VERSION ""

NS_ :

BS_:

BU_: DASH VectorDatalogger MotecDatalogger KvaserDatalogger PDM SENSOR_BOARD CAN_NODE_3 CAN_NODE_2 CAN_NODE_1 CAN_NODE_0 VCU BMS INV U2C

BO_ 3221225472 VECTOR__INDEPENDENT_SIG_MSG: 0 Vector__XXX
 SG_ OCT_GPS_TimeUCT : 0|25@1+ (0.01,0) [0|24000000] "" Vector__XXX
 SG_ OCT_GPS_NumSats : 0|7@1+ (1,0) [0|99] "" Vector__XXX
 SG_ OCT_GPS_HDOP : 0|8@1+ (1,0) [0|256] "" Vector__XXX
 SG_ OCT_GPS_Longitude : 0|32@1- (0.0001,0) [0|1809999999] "" Vector__XXX
 SG_ OCT_GPS_Latitude : 0|31@1- (0.0001,0) [0|909999999] "" Vector__XXX

BO_ 2033 VCU_Config_Torque_Map: 8 Vector__XXX
 SG_ MAX_Torque : 0|16@1+ (1,0) [0|0] "" Vector__XXX
 SG_ Torque_Map_Deadzone : 16|32@1- (1,0) [0|0] "" Vector__XXX

BO_ 2032 VCU_Config: 8 Vector__XXX
 SG_ VCU_CONFIG_Multiplexor M : 7|8@0- (1,0) [0|0] "" Vector__XXX
 SG_ BPS_MIN_Mapped m7 : 40|16@1+ (1,0) [0|0] "" Vector__XXX
 SG_ BPS_MIN_ADC m7 : 24|16@1+ (1,0) [0|0] "" Vector__XXX
 SG_ BPS_MAX_Mapped m7 : 8|16@1+ (1,0) [0|0] "" Vector__XXX
 SG_ BPS_MAX_ADC m6 : 40|16@1+ (1,0) [0|0] "" Vector__XXX
 SG_ BPS_Full_Press_FRACT m6 : 8|32@1- (1,0) [0|0] "" Vector__XXX
 SG_ APPS_MAX_Discrepancy m5 : 8|32@1+ (1,0) [0|0] "" Vector__XXX
 SG_ APPS2_OOB_FRACT m4 : 24|32@1- (1,0) [0|0] "" Vector__XXX
 SG_ APPS2_MIN_Mapped m4 : 8|16@1+ (1,0) [0|0] "" Vector__XXX
 SG_ APPS2_MIN_ADC m3 : 40|16@1+ (1,0) [0|0] "" Vector__XXX
 SG_ APPS2_MAX_Mapped m3 : 24|16@1+ (1,0) [0|0] "" Vector__XXX
 SG_ APPS2_MAX_ADC m3 : 8|16@1+ (1,0) [0|0] "" Vector__XXX
 SG_ APPS1_OOB_FRACT m2 : 24|32@1- (1,0) [0|0] "" Vector__XXX
 SG_ APPS1_MIN_Mapped m2 : 8|16@1+ (1,0) [0|0] "" Vector__XXX
 SG_ APPS1_MAX_Mapped m1 : 40|16@1+ (1,0) [0|0] "" Vector__XXX
 SG_ APPS1_MAX_ADC m1 : 24|16@1+ (1,0) [0|0] "" Vector__XXX
 SG_ APPS1_MIN_ADC m1 : 8|16@1+ (1,0) [0|0] "" Vector__XXX

BO_ 1664 SB_Strain: 3 SENSOR_BOARD
 SG_ SB_Strain_9 m9 : 8|16@1+ (1.953125E-06,-0.004) [-0.004|0.123998046875] "m/m" Vector__XXX
 SG_ SB_Strain_8 m8 : 8|16@1+ (1.953125E-06,-0.004) [-0.004|0.123998046875] "m/m" Vector__XXX
 SG_ SB_Strain_7 m7 : 8|16@1+ (1.953125E-06,-0.004) [-0.004|0.123998046875] "m/m" Vector__XXX
 SG_ SB_Strain_6 m6 : 8|16@1+ (1.953125E-06,-0.004) [-0.004|0.123998046875] "m/m" Vector__XXX
 SG_ SB_Strain_5 m5 : 8|16@1+ (1.953125E-06,-0.004) [-0.004|0.123998046875] "m/m" Vector__XXX
 SG_ SB_Strain_4 m4 : 8|16@1+ (1.953125E-06,-0.004) [-0.004|0.123998046875] "m/m" Vector__XXX
 SG_ SB_Strain_3 m3 : 8|16@1+ (1.953125E-06,-0.004) [-0.004|0.123998046875] "m/m" Vector__XXX
 SG_ SB_Strain_2 m2 : 8|16@1+ (1.953125E-06,-0.004) [-0.004|0.123998046875] "m/m" Vector__XXX
 SG_ SB_Strain_12 m12 : 8|16@1+ (1.953125E-06,-0.004) [-0.004|0.123998046875] "m/m" Vector__XXX
 SG_ SB_Strain_11 m11 : 8|16@1+ (1.953125E-06,-0.004) [-0.004|0.123998046875] "m/m" Vector__XXX
 SG_ SB_Strain_10 m10 : 8|16@1+ (1.953125E-06,-0.004) [-0.004|0.123998046875] "m/m" Vector__XXX
 SG_ SB_Strain_1 m1 : 8|16@1+ (1.953125E-06,-0.004) [-0.004|0.123998046875] "m/m" Vector__XXX
 SG_ SB_Strain_multiplexor M : 0|4@1- (1,0) [0|12] "Num" Vector__XXX

BO_ 1648 CAN_NODE_0: 8 CAN_NODE_0
 SG_ CAN_NODE_THERM_2 m2 : 16|8@1- (1,0) [-128|127] "�C"  DASH,KvaserDatalogger,MotecDatalogger,VectorDatalogger
 SG_ CAN_NODE_THERM_1 m2 : 8|8@1- (1,0) [-128|127] "�C"  DASH,KvaserDatalogger,MotecDatalogger,VectorDatalogger
 SG_ CAN_NODE_PD_9 m1 : 40|12@1+ (0.00402832,0) [0|16.4959704] "V"  DASH,KvaserDatalogger,MotecDatalogger,VectorDatalogger
 SG_ CAN_NODE_PD_8 m1 : 28|12@1+ (0.00402832,0) [0|16.4959704] "V"  DASH,KvaserDatalogger,MotecDatalogger,VectorDatalogger
 SG_ CAN_NODE_PD_7 m1 : 16|12@1+ (0.00402832,0) [0|16.4959704] "V"  DASH,KvaserDatalogger,MotecDatalogger,VectorDatalogger
 SG_ CAN_NODE_PD_6 m1 : 4|12@1+ (0.00402832,0) [0|16.4959704] "V"  DASH,KvaserDatalogger,MotecDatalogger,VectorDatalogger
 SG_ CAN_NODE_PD_5 m0 : 52|12@1+ (0.00402832,0) [0|16.4959704] "V"  DASH,KvaserDatalogger,MotecDatalogger,VectorDatalogger
 SG_ CAN_NODE_PD_4 m0 : 40|12@1+ (0.00402832,0) [0|16.4959704] "V"  DASH,KvaserDatalogger,MotecDatalogger,VectorDatalogger
 SG_ CAN_NODE_PD_3 m0 : 28|12@1+ (0.00402832,0) [0|16.4959704] "V"  DASH,KvaserDatalogger,MotecDatalogger,VectorDatalogger
 SG_ CAN_NODE_PD_2 m0 : 16|12@1+ (0.00402832,0) [0|16.4959704] "V"  DASH,KvaserDatalogger,MotecDatalogger,VectorDatalogger
 SG_ CAN_NODE_PD_10 m1 : 52|12@1+ (0.00402832,0) [0|16.4959704] "V"  DASH,KvaserDatalogger,MotecDatalogger,VectorDatalogger
 SG_ CAN_NODE_PD_1 m0 : 4|12@1+ (0.00402832,0) [0|16.4959704] "V"  DASH,KvaserDatalogger,MotecDatalogger,VectorDatalogger
 SG_ CAN_NODE_multiplexor M : 0|4@1+ (1,0) [0|15] ""  DASH,KvaserDatalogger,MotecDatalogger,VectorDatalogger

BO_ 1649 CAN_NODE_1: 8 CAN_NODE_1
 SG_ CAN_NODE_THERM_2 m2 : 16|8@1- (1,0) [-128|127] "�C"  DASH
 SG_ CAN_NODE_THERM_1 m2 : 8|8@1- (1,0) [-128|127] "�C"  DASH
 SG_ CAN_NODE_PD_9 m1 : 40|12@1+ (0.00402832,0) [0|16.4959704] "V"  DASH
 SG_ CAN_NODE_PD_8 m1 : 28|12@1+ (0.00402832,0) [0|16.4959704] "V"  DASH
 SG_ CAN_NODE_PD_7 m1 : 16|12@1+ (0.00402832,0) [0|16.4959704] "V"  DASH
 SG_ CAN_NODE_PD_6 m1 : 4|12@1+ (0.00402832,0) [0|16.4959704] "V"  DASH
 SG_ CAN_NODE_PD_5 m0 : 52|12@1+ (0.00402832,0) [0|16.4959704] "V"  DASH
 SG_ CAN_NODE_PD_4 m0 : 40|12@1+ (0.00402832,0) [0|16.4959704] "V"  DASH
 SG_ CAN_NODE_PD_3 m0 : 28|12@1+ (0.00402832,0) [0|16.4959704] "V"  DASH
 SG_ CAN_NODE_PD_2 m0 : 16|12@1+ (0.00402832,0) [0|16.4959704] "V"  DASH
 SG_ CAN_NODE_PD_10 m1 : 52|12@1+ (0.00402832,0) [0|16.4959704] "V"  DASH
 SG_ CAN_NODE_PD_1 m0 : 4|12@1+ (0.00402832,0) [0|16.4959704] "V"  DASH
 SG_ CAN_NODE_multiplexor M : 0|4@1+ (1,0) [0|15] ""  DASH

BO_ 1650 CAN_NODE_2: 8 CAN_NODE_2
 SG_ CAN_NODE_THERM_2 m2 : 16|8@1- (1,0) [-128|127] "�C"  DASH
 SG_ CAN_NODE_THERM_1 m2 : 8|8@1- (1,0) [-128|127] "�C"  DASH
 SG_ CAN_NODE_PD_9 m1 : 40|12@1+ (0.00402832,0) [0|16.4959704] "V"  DASH
 SG_ CAN_NODE_PD_8 m1 : 28|12@1+ (0.00402832,0) [0|16.4959704] "V"  DASH
 SG_ CAN_NODE_PD_7 m1 : 16|12@1+ (0.00402832,0) [0|16.4959704] "V"  DASH
 SG_ CAN_NODE_PD_6 m1 : 4|12@1+ (0.00402832,0) [0|16.4959704] "V"  DASH
 SG_ CAN_NODE_PD_5 m0 : 52|12@1+ (0.00402832,0) [0|16.4959704] "V"  DASH
 SG_ CAN_NODE_PD_4 m0 : 40|12@1+ (0.00402832,0) [0|16.4959704] "V"  DASH
 SG_ CAN_NODE_PD_3 m0 : 28|12@1+ (0.00402832,0) [0|16.4959704] "V"  DASH
 SG_ CAN_NODE_PD_2 m0 : 16|12@1+ (0.00402832,0) [0|16.4959704] "V"  DASH
 SG_ CAN_NODE_PD_10 m1 : 52|12@1+ (0.00402832,0) [0|16.4959704] "V"  DASH
 SG_ CAN_NODE_PD_1 m0 : 4|12@1+ (0.00402832,0) [0|16.4959704] "V"  DASH
 SG_ CAN_NODE_multiplexor M : 0|4@1+ (1,0) [0|15] ""  DASH

BO_ 1651 CAN_NODE_3: 8 CAN_NODE_3
 SG_ CAN_NODE_THERM_2 m2 : 16|8@1- (1,0) [-128|127] "�C"  DASH
 SG_ CAN_NODE_THERM_1 m2 : 8|8@1- (1,0) [-128|127] "�C"  DASH
 SG_ CAN_NODE_PD_9 m1 : 40|12@1+ (0.00402832,0) [0|16.4959704] "V"  DASH
 SG_ CAN_NODE_PD_8 m1 : 28|12@1+ (0.00402832,0) [0|16.4959704] "V"  DASH
 SG_ CAN_NODE_PD_7 m1 : 16|12@1+ (0.00402832,0) [0|16.4959704] "V"  DASH
 SG_ CAN_NODE_PD_6 m1 : 4|12@1+ (0.00402832,0) [0|16.4959704] "V"  DASH
 SG_ CAN_NODE_PD_5 m0 : 52|12@1+ (0.00402832,0) [0|16.4959704] "V"  DASH
 SG_ CAN_NODE_PD_4 m0 : 40|12@1+ (0.00402832,0) [0|16.4959704] "V"  DASH
 SG_ CAN_NODE_PD_3 m0 : 28|12@1+ (0.00402832,0) [0|16.4959704] "V"  DASH
 SG_ CAN_NODE_PD_2 m0 : 16|12@1+ (0.00402832,0) [0|16.4959704] "V"  DASH
 SG_ CAN_NODE_PD_10 m1 : 52|12@1+ (0.00402832,0) [0|16.4959704] "V"  DASH
 SG_ CAN_NODE_PD_1 m0 : 4|12@1+ (0.00402832,0) [0|16.4959704] "V"  DASH
 SG_ CAN_NODE_multiplexor M : 0|4@1+ (1,0) [0|15] ""  DASH

BO_ 1347 VCU_Temps: 8 VCU
 SG_ VCU_Max_Temp : 0|8@1- (1,0) [-128|127] "Celsius" Vector__XXX

BO_ 1301 PDM_In_Voltage: 8 PDM
 SG_ PDM_Serial_Number_L m4 : 56|8@1+ (1,0) [0|255] "V" Vector__XXX
 SG_ PDM_Serial_Number_H m4 : 48|8@1+ (1,0) [0|255] "V" Vector__XXX
 SG_ PDM_Firmware_Version_Minor m4 : 16|8@1+ (1,0) [0|255] "V" Vector__XXX
 SG_ PDM_Firmware_Version_Major m4 : 8|8@1+ (1,0) [0|255] "V" Vector__XXX
 SG_ PDM_Firmware_Version_Letter m4 : 24|8@1+ (1,0) [0|255] "V" Vector__XXX
 SG_ PDM_Input_9_Voltage m1 : 16|8@1+ (0.2,0) [0|51] "V" Vector__XXX
 SG_ PDM_Input_8_Voltage m1 : 8|8@1+ (0.2,0) [0|51] "V" Vector__XXX
 SG_ PDM_Input_7_Voltage m0 : 56|8@1+ (0.2,0) [0|51] "V" Vector__XXX
 SG_ PDM_Input_6_Voltage m0 : 48|8@1+ (0.2,0) [0|51] "V" Vector__XXX
 SG_ PDM_Input_5_Voltage m0 : 40|8@1+ (0.2,0) [0|51] "V" Vector__XXX
 SG_ PDM_Input_4_Voltage m0 : 32|8@1+ (0.2,0) [0|51] "V" Vector__XXX
 SG_ PDM_Input_3_Voltage m0 : 24|8@1+ (0.2,0) [0|51] "V" Vector__XXX
 SG_ PDM_Input_2_Voltage m0 : 16|8@1+ (0.2,0) [0|51] "V" Vector__XXX
 SG_ PDM_Input_23_Voltage m3 : 16|8@1+ (0.2,0) [0|51] "V" Vector__XXX
 SG_ PDM_Input_22_Voltage m3 : 8|8@1+ (0.2,0) [0|51] "V" Vector__XXX
 SG_ PDM_Input_21_Voltage m2 : 56|8@1+ (0.2,0) [0|51] "V" Vector__XXX
 SG_ PDM_Input_20_Voltage m2 : 48|8@1+ (0.2,0) [0|51] "V" Vector__XXX
 SG_ PDM_Input_19_Voltage m2 : 40|8@1+ (0.2,0) [0|51] "V" Vector__XXX
 SG_ PDM_Input_18_Voltage m2 : 32|8@1+ (0.2,0) [0|51] "V" Vector__XXX
 SG_ PDM_Input_17_Voltage m2 : 24|8@1+ (0.2,0) [0|51] "V" Vector__XXX
 SG_ PDM_Input_16_Voltage m2 : 16|8@1+ (0.2,0) [0|51] "V" Vector__XXX
 SG_ PDM_Input_15_Voltage m2 : 8|8@1+ (0.2,0) [0|51] "V" Vector__XXX
 SG_ PDM_Input_14_Voltage m1 : 56|8@1+ (0.2,0) [0|51] "V" Vector__XXX
 SG_ PDM_Input_13_Voltage m1 : 48|8@1+ (0.2,0) [0|51] "V" Vector__XXX
 SG_ PDM_Input_12_Voltage m1 : 40|8@1+ (0.2,0) [0|51] "V" Vector__XXX
 SG_ PDM_Input_11_Voltage m1 : 32|8@1+ (0.2,0) [0|51] "V" Vector__XXX
 SG_ PDM_Input_10_Voltage m1 : 24|8@1+ (0.2,0) [0|51] "V" Vector__XXX
 SG_ PDM_Input_1_Voltage m0 : 8|8@1+ (0.2,0) [0|51] "V" Vector__XXX
 SG_ PDM_In_Voltage_Compound_ID M : 0|8@1- (1,0) [0|0] "" Vector__XXX

BO_ 1300 PDM_Out_Status: 8 PDM
 SG_ PDM_Output_9_Status m1 : 0|6@1+ (1,0) [0|63] "Off/On" Vector__XXX
 SG_ PDM_Output_8_Status m0 : 56|8@1+ (1,0) [0|255] "Off/On" Vector__XXX
 SG_ PDM_Output_7_Status m0 : 48|8@1+ (1,0) [0|255] "Off/On" Vector__XXX
 SG_ PDM_Output_6_Status m0 : 40|8@1+ (1,0) [0|255] "Off/On" Vector__XXX
 SG_ PDM_Output_5_Status m0 : 32|8@1+ (1,0) [0|255] "Off/On" Vector__XXX
 SG_ PDM_Output_4_Status m0 : 24|8@1+ (1,0) [0|255] "Off/On" Vector__XXX
 SG_ PDM_Output_3_Status m0 : 16|8@1+ (1,0) [0|255] "Off/On" Vector__XXX
 SG_ PDM_Output_32_Status m3 : 56|8@1+ (1,0) [0|255] "Off/On" Vector__XXX
 SG_ PDM_Output_31_Status m3 : 48|8@1+ (1,0) [0|255] "Off/On" Vector__XXX
 SG_ PDM_Output_30_Status m3 : 40|8@1+ (1,0) [0|255] "Off/On" Vector__XXX
 SG_ PDM_Output_2_Status m0 : 8|8@1+ (1,0) [0|255] "Off/On" Vector__XXX
 SG_ PDM_Output_29_Status m3 : 32|8@1+ (1,0) [0|255] "Off/On" Vector__XXX
 SG_ PDM_Output_28_Status m3 : 24|8@1+ (1,0) [0|255] "Off/On" Vector__XXX
 SG_ PDM_Output_27_Status m3 : 16|8@1+ (1,0) [0|255] "Off/On" Vector__XXX
 SG_ PDM_Output_26_Status m3 : 8|8@1+ (1,0) [0|255] "Off/On" Vector__XXX
 SG_ PDM_Output_25_Status m3 : 0|6@1+ (1,0) [0|63] "Off/On" Vector__XXX
 SG_ PDM_Output_24_Status m2 : 56|8@1+ (1,0) [0|255] "Off/On" Vector__XXX
 SG_ PDM_Output_23_Status m2 : 48|8@1+ (1,0) [0|255] "Off/On" Vector__XXX
 SG_ PDM_Output_22_Status m2 : 40|8@1+ (1,0) [0|255] "Off/On" Vector__XXX
 SG_ PDM_Output_21_Status m2 : 32|8@1+ (1,0) [0|255] "Off/On" Vector__XXX
 SG_ PDM_Output_20_Status m2 : 24|8@1+ (1,0) [0|255] "Off/On" Vector__XXX
 SG_ PDM_Output_19_Status m2 : 16|8@1+ (1,0) [0|255] "Off/On" Vector__XXX
 SG_ PDM_Output_18_Status m2 : 8|8@1+ (1,0) [0|255] "Off/On" Vector__XXX
 SG_ PDM_Output_17_Status m2 : 0|6@1+ (1,0) [0|63] "Off/On" Vector__XXX
 SG_ PDM_Output_16_Status m1 : 56|8@1+ (1,0) [0|255] "Off/On" Vector__XXX
 SG_ PDM_Output_15_Status m1 : 48|8@1+ (1,0) [0|255] "Off/On" Vector__XXX
 SG_ PDM_Output_14_Status m1 : 40|8@1+ (1,0) [0|255] "Off/On" Vector__XXX
 SG_ PDM_Output_13_Status m1 : 32|8@1+ (1,0) [0|255] "Off/On" Vector__XXX
 SG_ PDM_Output_12_Status m1 : 24|8@1+ (1,0) [0|255] "Off/On" Vector__XXX
 SG_ PDM_Output_11_Status m1 : 16|8@1+ (1,0) [0|255] "Off/On" Vector__XXX
 SG_ PDM_Output_10_Status m1 : 8|8@1+ (1,0) [0|255] "Off/On" Vector__XXX
 SG_ PDM_Output_1_Status m0 : 0|6@1+ (1,0) [0|63] "Off/On" Vector__XXX
 SG_ PDM_Out_Status_Compound_ID M : 6|2@1- (1,0) [0|0] "Off/On" Vector__XXX

BO_ 1299 PDM_Out_Voltage: 8 PDM
 SG_ PDM_Output_9_Voltage m1 : 16|8@1+ (0.2,0) [0|51] "V" Vector__XXX
 SG_ PDM_Output_8_Voltage m1 : 8|8@1+ (0.2,0) [0|51] "V" Vector__XXX
 SG_ PDM_Output_7_Voltage m0 : 56|8@1+ (0.2,0) [0|51] "V" Vector__XXX
 SG_ PDM_Output_6_Voltage m0 : 48|8@1+ (0.2,0) [0|51] "V" Vector__XXX
 SG_ PDM_Output_5_Voltage m0 : 40|8@1+ (0.2,0) [0|51] "V" Vector__XXX
 SG_ PDM_Output_4_Voltage m0 : 32|8@1+ (0.2,0) [0|51] "V" Vector__XXX
 SG_ PDM_Output_3_Voltage m0 : 24|8@1+ (0.2,0) [0|51] "V" Vector__XXX
 SG_ PDM_Output_32_Voltage m4 : 32|8@1+ (0.2,0) [0|51] "V" Vector__XXX
 SG_ PDM_Output_31_Voltage m4 : 24|8@1+ (0.2,0) [0|51] "V" Vector__XXX
 SG_ PDM_Output_30_Voltage m4 : 16|8@1+ (0.2,0) [0|51] "V" Vector__XXX
 SG_ PDM_Output_2_Voltage m0 : 16|8@1+ (0.2,0) [0|51] "V" Vector__XXX
 SG_ PDM_Output_29_Voltage m4 : 8|8@1+ (0.2,0) [0|51] "V" Vector__XXX
 SG_ PDM_Output_28_Voltage m3 : 56|8@1+ (0.2,0) [0|51] "V" Vector__XXX
 SG_ PDM_Output_27_Voltage m3 : 48|8@1+ (0.2,0) [0|51] "V" Vector__XXX
 SG_ PDM_Output_26_Voltage m3 : 40|8@1+ (0.2,0) [0|51] "V" Vector__XXX
 SG_ PDM_Output_25_Voltage m3 : 32|8@1+ (0.2,0) [0|51] "V" Vector__XXX
 SG_ PDM_Output_24_Voltage m3 : 24|8@1+ (0.2,0) [0|51] "V" Vector__XXX
 SG_ PDM_Output_23_Voltage m3 : 16|8@1+ (0.2,0) [0|51] "V" Vector__XXX
 SG_ PDM_Output_22_Voltage m3 : 8|8@1+ (0.2,0) [0|51] "V" Vector__XXX
 SG_ PDM_Output_21_Voltage m2 : 56|8@1+ (0.2,0) [0|51] "V" Vector__XXX
 SG_ PDM_Output_20_Voltage m2 : 48|8@1+ (0.2,0) [0|51] "V" Vector__XXX
 SG_ PDM_Output_1_Voltage m0 : 8|8@1+ (0.2,0) [0|51] "V" Vector__XXX
 SG_ PDM_Output_19_Voltage m2 : 40|8@1+ (0.2,0) [0|51] "V" Vector__XXX
 SG_ PDM_Output_18_Voltage m2 : 32|8@1+ (0.2,0) [0|51] "V" Vector__XXX
 SG_ PDM_Output_17_Voltage m2 : 24|8@1+ (0.2,0) [0|51] "V" Vector__XXX
 SG_ PDM_Output_16_Voltage m2 : 16|8@1+ (0.2,0) [0|51] "V" Vector__XXX
 SG_ PDM_Output_15_Voltage m2 : 8|8@1+ (0.2,0) [0|51] "V" Vector__XXX
 SG_ PDM_Output_14_Voltage m1 : 56|8@1+ (0.2,0) [0|51] "V" Vector__XXX
 SG_ PDM_Output_13_Voltage m1 : 48|8@1+ (0.2,0) [0|51] "V" Vector__XXX
 SG_ PDM_Output_12_Voltage m1 : 40|8@1+ (0.2,0) [0|51] "V" Vector__XXX
 SG_ PDM_Output_11_Voltage m1 : 32|8@1+ (0.2,0) [0|51] "V" Vector__XXX
 SG_ PDM_Output_10_Voltage m1 : 24|8@1+ (0.2,0) [0|51] "V" Vector__XXX
 SG_ PDM_Out_Voltage_Compound_ID M : 0|8@1- (1,0) [0|0] "V" Vector__XXX

BO_ 1298 PDM_Out_Load: 8 PDM
 SG_ PDM_Output_9_Load m1 : 16|8@1+ (1,0) [0|255] "%" Vector__XXX
 SG_ PDM_Output_8_Load m1 : 8|8@1+ (1,0) [0|255] "%" Vector__XXX
 SG_ PDM_Output_7_Load m0 : 56|8@1+ (1,0) [0|255] "%" Vector__XXX
 SG_ PDM_Output_6_Load m0 : 48|8@1+ (1,0) [0|255] "%" Vector__XXX
 SG_ PDM_Output_5_Load m0 : 40|8@1+ (1,0) [0|255] "%" Vector__XXX
 SG_ PDM_Output_4_Load m0 : 32|8@1+ (1,0) [0|255] "%" Vector__XXX
 SG_ PDM_Output_3_Load m0 : 24|8@1+ (1,0) [0|255] "%" Vector__XXX
 SG_ PDM_Output_32_Load m4 : 32|8@1+ (1,0) [0|255] "%" Vector__XXX
 SG_ PDM_Output_31_Load m4 : 24|8@1+ (1,0) [0|255] "%" Vector__XXX
 SG_ PDM_Output_30_Load m4 : 16|8@1+ (1,0) [0|255] "%" Vector__XXX
 SG_ PDM_Output_2_Load m0 : 16|8@1+ (1,0) [0|255] "%" Vector__XXX
 SG_ PDM_Output_29_Load m4 : 8|8@1+ (1,0) [0|255] "%" Vector__XXX
 SG_ PDM_Output_28_Load m3 : 56|8@1+ (1,0) [0|255] "%" Vector__XXX
 SG_ PDM_Output_27_Load m3 : 48|8@1+ (1,0) [0|255] "%" Vector__XXX
 SG_ PDM_Output_26_Load m3 : 40|8@1+ (1,0) [0|255] "%" Vector__XXX
 SG_ PDM_Output_25_Load m3 : 32|8@1+ (1,0) [0|255] "%" Vector__XXX
 SG_ PDM_Output_24_Load m3 : 24|8@1+ (1,0) [0|255] "%" Vector__XXX
 SG_ PDM_Output_23_Load m3 : 16|8@1+ (1,0) [0|255] "%" Vector__XXX
 SG_ PDM_Output_22_Load m3 : 8|8@1+ (1,0) [0|255] "%" Vector__XXX
 SG_ PDM_Output_21_Load m2 : 56|8@1+ (1,0) [0|255] "%" Vector__XXX
 SG_ PDM_Output_20_Load m2 : 48|8@1+ (1,0) [0|255] "%" Vector__XXX
 SG_ PDM_Output_19_Load m2 : 40|8@1+ (1,0) [0|255] "%" Vector__XXX
 SG_ PDM_Output_18_Load m2 : 32|8@1+ (1,0) [0|255] "%" Vector__XXX
 SG_ PDM_Output_17_Load m2 : 24|8@1+ (1,0) [0|255] "%" Vector__XXX
 SG_ PDM_Output_16_Load m2 : 16|8@1+ (1,0) [0|255] "%" Vector__XXX
 SG_ PDM_Output_15_Load m2 : 8|8@1+ (1,0) [0|255] "%" Vector__XXX
 SG_ PDM_Output_14_Load m1 : 56|8@1+ (1,0) [0|255] "%" Vector__XXX
 SG_ PDM_Output_13_Load m1 : 48|8@1+ (1,0) [0|255] "%" Vector__XXX
 SG_ PDM_Output_12_Load m1 : 40|8@1+ (1,0) [0|255] "%" Vector__XXX
 SG_ PDM_Output_11_Load m1 : 32|8@1+ (1,0) [0|255] "%" Vector__XXX
 SG_ PDM_Output_10_Load m1 : 24|8@1+ (1,0) [0|255] "%" Vector__XXX
 SG_ PDM_Output_1_Load m0 : 8|8@1+ (1,0) [0|255] "%" Vector__XXX
 SG_ PDM_Out_Load_Compound_ID M : 0|8@1- (1,0) [0|240] "" Vector__XXX

BO_ 1297 PDM_Out_Current: 8 PDM
 SG_ PDM_Output_8_Current m1 : 8|8@1+ (0.5,0) [0|127.5] "A" Vector__XXX
 SG_ PDM_Output_7_Current m0 : 56|8@1+ (0.5,0) [0|127.5] "A" Vector__XXX
 SG_ PDM_Output_6_Current m0 : 48|8@1+ (0.5,0) [0|127.5] "A" Vector__XXX
 SG_ PDM_Output_5_Current m0 : 40|8@1+ (0.5,0) [0|127.5] "A" Vector__XXX
 SG_ PDM_Output_4_Current m0 : 32|8@1+ (0.5,0) [0|127.5] "A" Vector__XXX
 SG_ PDM_Output_3_Current m0 : 24|8@1+ (0.5,0) [0|127.5] "A" Vector__XXX
 SG_ PDM_Output_2_Current m0 : 16|8@1+ (0.5,0) [0|127.5] "A" Vector__XXX
 SG_ PDM_Output_1_Current m0 : 8|8@1+ (0.5,0) [0|127.5] "A" Vector__XXX
 SG_ PDM_Out_Current_Compound_ID M : 4|4@1- (1,0) [0|240] "A" Vector__XXX
 SG_ PDM_Output_9_Current m1 : 16|8@1+ (0.2,0) [0|51] "A" Vector__XXX
 SG_ PDM_Output_32_Current m4 : 32|8@1+ (0.2,0) [0|51] "A" Vector__XXX
 SG_ PDM_Output_31_Current m4 : 24|8@1+ (0.2,0) [0|51] "A" Vector__XXX
 SG_ PDM_Output_30_Current m4 : 16|8@1+ (0.2,0) [0|51] "A" Vector__XXX
 SG_ PDM_Output_29_Current m4 : 8|8@1+ (0.2,0) [0|51] "A" Vector__XXX
 SG_ PDM_Output_28_Current m3 : 56|8@1+ (0.2,0) [0|51] "A" Vector__XXX
 SG_ PDM_Output_27_Current m3 : 48|8@1+ (0.2,0) [0|51] "A" Vector__XXX
 SG_ PDM_Output_26_Current m3 : 40|8@1+ (0.2,0) [0|51] "A" Vector__XXX
 SG_ PDM_Output_25_Current m3 : 32|8@1+ (0.2,0) [0|51] "A" Vector__XXX
 SG_ PDM_Output_24_Current m3 : 24|8@1+ (0.2,0) [0|51] "A" Vector__XXX
 SG_ PDM_Output_23_Current m3 : 16|8@1+ (0.2,0) [0|51] "A" Vector__XXX
 SG_ PDM_Output_22_Current m3 : 8|8@1+ (0.2,0) [0|51] "A" Vector__XXX
 SG_ PDM_Output_21_Current m2 : 56|8@1+ (0.2,0) [0|51] "A" Vector__XXX
 SG_ PDM_Output_20_Current m2 : 48|8@1+ (0.2,0) [0|51] "A" Vector__XXX
 SG_ PDM_Output_19_Current m2 : 40|8@1+ (0.2,0) [0|51] "A" Vector__XXX
 SG_ PDM_Output_18_Current m2 : 32|8@1+ (0.2,0) [0|51] "A" Vector__XXX
 SG_ PDM_Output_17_Current m2 : 24|8@1+ (0.2,0) [0|51] "A" Vector__XXX
 SG_ PDM_Output_16_Current m2 : 16|8@1+ (0.2,0) [0|51] "A" Vector__XXX
 SG_ PDM_Output_15_Current m2 : 8|8@1+ (0.2,0) [0|51] "A" Vector__XXX
 SG_ PDM_Output_14_Current m1 : 56|8@1+ (0.2,0) [0|51] "A" Vector__XXX
 SG_ PDM_Output_13_Current m1 : 48|8@1+ (0.2,0) [0|51] "A" Vector__XXX
 SG_ PDM_Output_12_Current m1 : 40|8@1+ (0.2,0) [0|51] "A" Vector__XXX
 SG_ PDM_Output_11_Current m1 : 32|8@1+ (0.2,0) [0|51] "A" Vector__XXX
 SG_ PDM_Output_10_Current m1 : 24|8@1+ (0.2,0) [0|51] "A" Vector__XXX

BO_ 1296 PDM_State: 8 PDM
 SG_ PDM_Output_Fault_9_16 m4 : 48|8@1- (1,0) [0|0] "Off/On" Vector__XXX
 SG_ PDM_Output_Fault_25_32 m4 : 32|8@1- (1,0) [0|0] "Off/On" Vector__XXX
 SG_ PDM_Output_Fault_1_8 m4 : 56|8@1- (1,0) [0|0] "Off/On" Vector__XXX
 SG_ PDM_Output_Fault_17_24 m4 : 40|8@1- (1,0) [0|0] "Off/On" Vector__XXX
 SG_ PDM_Total_Current m3 : 32|8@1+ (1,0) [0|255] "A" Vector__XXX
 SG_ PDM_Reset_Source m3 : 48|8@1- (1,0) [0|0] "Off/On" Vector__XXX
 SG_ PDM_Global_Error_Flag m3 : 24|8@1- (1,0) [0|0] "Off/On" Vector__XXX
 SG_ PDM_9V5_Internal m3 : 40|8@1+ (0.0615,0) [0|15.6825] "V" Vector__XXX
 SG_ PDM_Battery_Voltage m3 : 16|8@1+ (0.1216,0) [0|31.008] "V" Vector__XXX
 SG_ PDM_Internal_Temp m3 : 8|8@1+ (2,0) [0|125] "C" Vector__XXX
 SG_ PDM_State_Compound_ID M : 4|4@1- (1,0) [0|240] "Off/On" Vector__XXX
 SG_ PDM_Input_23_State m2 : 48|1@1- (1,0) [0|0] "Off/On" Vector__XXX
 SG_ PDM_Input_22_State m2 : 40|1@1- (1,0) [0|0] "Off/On" Vector__XXX
 SG_ PDM_Input_21_State m2 : 32|1@1- (1,0) [0|0] "Off/On" Vector__XXX
 SG_ PDM_Input_20_State m2 : 24|1@1- (1,0) [0|0] "Off/On" Vector__XXX
 SG_ PDM_Input_19_State m2 : 16|1@1- (1,0) [0|0] "Off/On" Vector__XXX
 SG_ PDM_Input_18_State m2 : 8|1@1- (1,0) [0|0] "Off/On" Vector__XXX
 SG_ PDM_Input_17_State m2 : 0|1@1- (1,0) [0|0] "Off/On" Vector__XXX
 SG_ PDM_Input_16_State m1 : 56|1@1- (1,0) [0|0] "Off/On" Vector__XXX
 SG_ PDM_Input_15_State m1 : 48|1@1- (1,0) [0|0] "Off/On" Vector__XXX
 SG_ PDM_Input_14_State m1 : 40|1@1- (1,0) [0|0] "Off/On" Vector__XXX
 SG_ PDM_Input_13_State m1 : 32|1@1- (1,0) [0|0] "Off/On" Vector__XXX
 SG_ PDM_Input_12_State m1 : 24|1@1- (1,0) [0|0] "Off/On" Vector__XXX
 SG_ PDM_Input_11_State m1 : 16|1@1- (1,0) [0|0] "Off/On" Vector__XXX
 SG_ PDM_Input_10_State m1 : 8|1@1- (1,0) [0|0] "Off/On" Vector__XXX
 SG_ PDM_Input_9_State m1 : 0|1@1- (1,0) [0|0] "Off/On" Vector__XXX
 SG_ PDM_Input_8_State m0 : 56|1@1- (1,7) [0|1] "Off/On" Vector__XXX
 SG_ PDM_Input_7_State m0 : 48|1@1- (1,6) [0|1] "Off/On" Vector__XXX
 SG_ PDM_Input_6_State m0 : 40|1@1- (1,5) [0|1] "Off/On" Vector__XXX
 SG_ PDM_Input_5_State m0 : 32|1@1- (1,4) [0|1] "Off/On" Vector__XXX
 SG_ PDM_Input_4_State m0 : 24|1@1- (1,3) [0|1] "Off/On" Vector__XXX
 SG_ PDM_Input_3_State m0 : 16|1@1- (1,12) [0|1] "Off/On" Vector__XXX
 SG_ PDM_Input_2_State m0 : 8|1@1- (1,9) [0|1] "Off/On" Vector__XXX
 SG_ PDM_Input_1_State m0 : 0|1@1- (1,0) [0|1] "Off/On" Vector__XXX

BO_ 64 VCU_Ping: 8 VCU

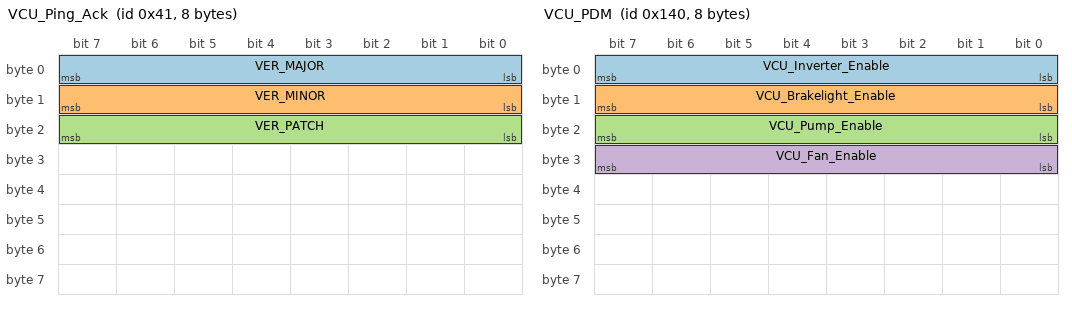
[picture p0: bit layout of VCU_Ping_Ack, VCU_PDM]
BO_ 65 VCU_Ping_Ack: 8 VCU
 SG_ VER_MAJOR : 0|8@1+ (1,0) [0|0] "" Vector__XXX
 SG_ VER_MINOR : 8|8@1+ (1,0) [0|0] "" Vector__XXX
 SG_ VER_PATCH : 16|8@1+ (1,0) [0|0] "" Vector__XXX

BO_ 66 VCU_TS_On: 8 VCU

BO_ 320 VCU_PDM: 8 VCU
 SG_ VCU_Inverter_Enable : 0|8@1+ (1,0) [0|1] "On/Off"  PDM
 SG_ VCU_Brakelight_Enable : 8|8@1+ (1,0) [0|1] "On/Off"  PDM
 SG_ VCU_Pump_Enable : 16|8@1+ (1,0) [0|1] "On/Off"  PDM
 SG_ VCU_Fan_Enable : 24|8@1+ (1,0) [0|1] "On/Off"  PDM

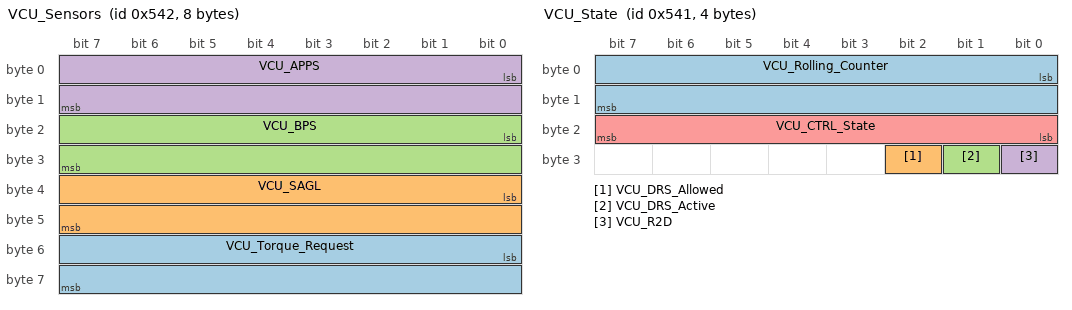
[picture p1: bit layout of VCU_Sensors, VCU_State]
BO_ 1346 VCU_Sensors: 8 VCU
 SG_ VCU_Torque_Request : 48|16@1+ (0.1,0) [0|6553.5] "Nm" Vector__XXX
 SG_ VCU_SAGL : 32|16@1+ (0.1,0) [0|100] "deg" Vector__XXX
 SG_ VCU_BPS : 16|16@1+ (0.1,0) [0|100] "" Vector__XXX
 SG_ VCU_APPS : 0|16@1+ (0.1,0) [0|100] "%" Vector__XXX

BO_ 1345 VCU_State: 4 VCU
 SG_ VCU_Rolling_Counter : 0|16@1+ (1,0) [0|65535] "" Vector__XXX
 SG_ VCU_DRS_Allowed : 26|1@1+ (1,0) [0|1] "" Vector__XXX
 SG_ VCU_DRS_Active : 25|1@1+ (1,0) [0|1] "" Vector__XXX
 SG_ VCU_R2D : 24|1@1+ (1,0) [0|1] "" Vector__XXX
 SG_ VCU_CTRL_State : 16|8@1+ (1,0) [0|255] "" Vector__XXX

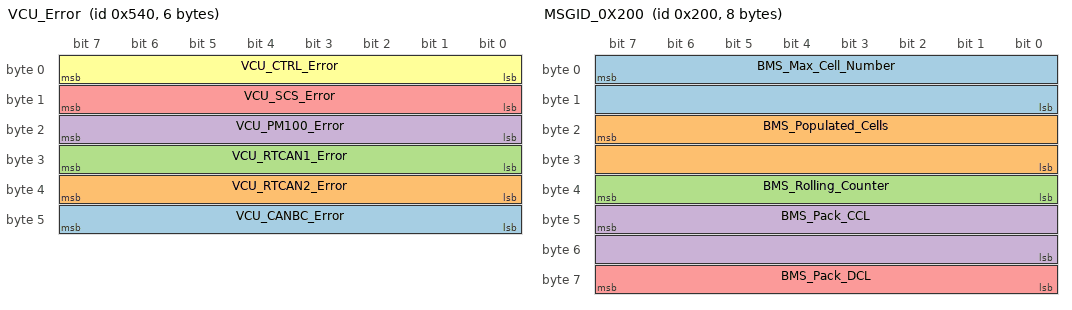
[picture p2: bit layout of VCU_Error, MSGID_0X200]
BO_ 1344 VCU_Error: 6 VCU
 SG_ VCU_CANBC_Error : 40|8@1+ (1,0) [0|255] "" Vector__XXX
 SG_ VCU_RTCAN2_Error : 32|8@1+ (1,0) [0|255] "" Vector__XXX
 SG_ VCU_RTCAN1_Error : 24|8@1+ (1,0) [0|255] "" Vector__XXX
 SG_ VCU_PM100_Error : 16|8@1+ (1,0) [0|255] "" Vector__XXX
 SG_ VCU_SCS_Error : 8|8@1+ (1,0) [0|255] "" Vector__XXX
 SG_ VCU_CTRL_Error : 0|8@1+ (1,0) [0|255] "" Vector__XXX

BO_ 512 MSGID_0X200: 8 BMS
 SG_ BMS_Max_Cell_Number : 7|16@0+ (1,0) [0|0] "Num" Vector__XXX
 SG_ BMS_Populated_Cells : 23|16@0+ (1,0) [0|0] "Num" Vector__XXX
 SG_ BMS_Rolling_Counter : 39|8@0+ (1,0) [0|0] "Num" Vector__XXX
 SG_ BMS_Pack_CCL : 47|16@0+ (1,0) [0|0] "Amps" Vector__XXX
 SG_ BMS_Pack_DCL : 63|8@0+ (1,1720) [0|0] "Amps" Vector__XXX

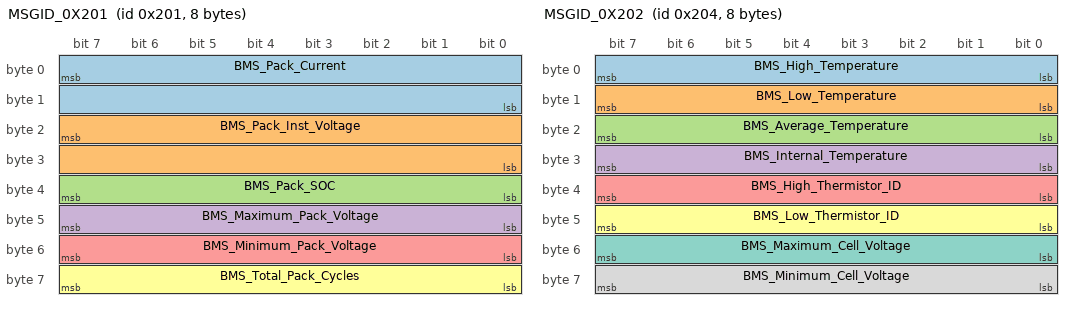
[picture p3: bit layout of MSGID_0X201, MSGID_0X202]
BO_ 513 MSGID_0X201: 8 BMS
 SG_ BMS_Pack_Current : 7|16@0+ (0.1,0) [0|0] "Amps" Vector__XXX
 SG_ BMS_Pack_Inst_Voltage : 23|16@0+ (0.1,0) [0|0] "Volts" Vector__XXX
 SG_ BMS_Pack_SOC : 39|8@0+ (0.5,0) [0|0] "Percent" Vector__XXX
 SG_ BMS_Maximum_Pack_Voltage : 47|8@0+ (0.1,0) [0|0] "Volts" Vector__XXX
 SG_ BMS_Minimum_Pack_Voltage : 55|8@0+ (0.1,0) [0|0] "Volts" Vector__XXX
 SG_ BMS_Total_Pack_Cycles : 63|8@0+ (1,1721) [0|0] "Num" Vector__XXX

BO_ 516 MSGID_0X202: 8 BMS
 SG_ BMS_High_Temperature : 7|8@0+ (1,0) [0|0] "Celsius" Vector__XXX
 SG_ BMS_Low_Temperature : 15|8@0+ (1,0) [0|0] "Celsius" Vector__XXX
 SG_ BMS_Average_Temperature : 23|8@0+ (1,0) [0|0] "Celsius" Vector__XXX
 SG_ BMS_Internal_Temperature : 31|8@0+ (1,0) [0|0] "Celsius" Vector__XXX
 SG_ BMS_High_Thermistor_ID : 39|8@0+ (1,0) [0|0] "ID" Vector__XXX
 SG_ BMS_Low_Thermistor_ID : 47|8@0+ (1,0) [0|0] "ID" Vector__XXX
 SG_ BMS_Maximum_Cell_Voltage : 55|8@0+ (0.0001,0) [0|0] "Volts" Vector__XXX
 SG_ BMS_Minimum_Cell_Voltage : 63|8@0+ (0.0001,0) [0|0] "Volts" Vector__XXX

BO_ 515 MSGID_0X203: 7 BMS
 SG_ BMS_High_Cell_Voltage_ID : 0|8@1+ (1,0) [0|0] "ID" Vector__XXX
 SG_ BMS_Low_Cell_Voltage_ID : 8|8@1+ (1,0) [0|0] "ID" Vector__XXX
 SG_ BMS_Discharge_Relay : 16|1@1+ (1,0) [0|1] "" Vector__XXX
 SG_ BMS_Charge_Relay : 17|1@1+ (1,0) [0|1] "" Vector__XXX
 SG_ BMS_Charger_Safety : 18|1@1+ (1,0) [0|1] "" Vector__XXX
 SG_ BMS_Charge_Interlock : 19|1@1+ (1,0) [0|1] "" Vector__XXX
 SG_ BMS_Balancing_Active : 20|1@1+ (1,0) [0|1] "" Vector__XXX
 SG_ BMS_FAULT_Int_Cell_Comms : 24|1@1+ (1,0) [0|1] "" Vector__XXX
 SG_ BMS_FAULT_Cell_Bal_Stuck_Off : 25|1@1+ (1,0) [0|1] "" Vector__XXX
 SG_ BMS_FAULT_Weak_Cell : 26|1@1+ (1,0) [0|1] "" Vector__XXX
 SG_ BMS_FAULT_Low_Cell_Voltage : 27|1@1+ (1,0) [0|1] "" Vector__XXX
 SG_ BMS_FAULT_Cell_Open_Wiring : 28|1@1+ (1,0) [0|1] "" Vector__XXX
 SG_ BMS_FAULT_Current_Sensor : 29|1@1+ (1,0) [0|1] "" Vector__XXX
 SG_ BMS_FAULT_Cell_Voltage_Over_5V : 30|1@1+ (1,0) [0|1] "" Vector__XXX
 SG_ BMS_FAULT_Cell_Bank : 31|1@1+ (1,0) [0|1] "" Vector__XXX
 SG_ BMS_FAULT_Weak_Pack : 32|1@1+ (1,0) [0|1] "" Vector__XXX
 SG_ BMS_FAULT_Fan_Monitor : 33|1@1+ (1,0) [0|1] "" Vector__XXX
 SG_ BMS_FAULT_Thermistor : 34|1@1+ (1,0) [0|1] "" Vector__XXX
 SG_ BMS_FAULT_CAN_Communication : 35|1@1+ (1,0) [0|1] "" Vector__XXX
 SG_ BMS_FAULT_Redundant_Power_Supply : 36|1@1+ (1,0) [0|1] "" Vector__XXX
 SG_ BMS_FAULT_High_Voltage_Isolation : 37|1@1+ (1,0) [0|1] "" Vector__XXX
 SG_ BMS_FAULT_Invld_Input_Sply_Volt : 38|1@1+ (1,0) [0|1] "" Vector__XXX
 SG_ BMS_FAULT_ChargeEnable_Relay : 39|1@1+ (1,0) [0|1] "" Vector__XXX
 SG_ BMS_FAULT_DischargeEnable_Relay : 40|1@1+ (1,0) [0|1] "" Vector__XXX
 SG_ BMS_FAULT_Charger_Safety_Relay : 41|1@1+ (1,0) [0|1] "" Vector__XXX
 SG_ BMS_FAULT_Internal_Hardware : 42|1@1+ (1,0) [0|1] "" Vector__XXX
 SG_ BMS_FAULT_Internal_Temp : 43|1@1+ (1,0) [0|1] "" Vector__XXX
 SG_ BMS_FAULT_Internal_Logic : 44|1@1+ (1,0) [0|1] "" Vector__XXX
 SG_ BMS_FAULT_Hi_Cell_Voltage_High : 45|1@1+ (1,0) [0|1] "" Vector__XXX
 SG_ BMS_FAULT_Lo_Cell_Voltage_Low : 46|1@1+ (1,0) [0|1] "" Vector__XXX
 SG_ BMS_FAULT_Pack_Too_Hot : 47|1@1+ (1,0) [0|1] "" Vector__XXX
 SG_ BMS_FAULT_Hi_Volt_Intlck_Signal : 48|1@1+ (1,0) [0|1] "" Vector__XXX
 SG_ BMS_FAULT_Prchrg_Malfunction : 49|1@1+ (1,0) [0|1] "" Vector__XXX
 SG_ BMS_FAULT_Abnormal_SoC_Behavior : 50|1@1+ (1,0) [0|1] "" Vector__XXX

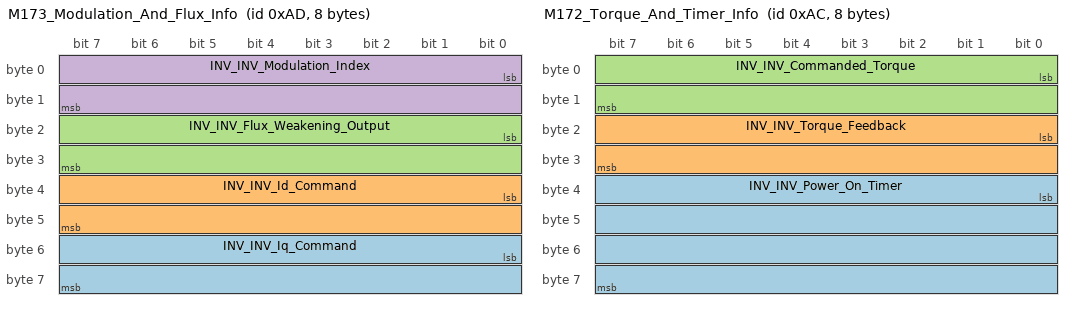
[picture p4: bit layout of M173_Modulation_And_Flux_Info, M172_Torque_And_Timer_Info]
BO_ 173 M173_Modulation_And_Flux_Info: 8 INV
 SG_ INV_INV_Iq_Command : 48|16@1- (0.1,0) [-3276.8|3276.7] "A" Vector__XXX
 SG_ INV_INV_Id_Command : 32|16@1- (0.1,0) [-3276.8|3276.7] "A" Vector__XXX
 SG_ INV_INV_Flux_Weakening_Output : 16|16@1- (0.1,0) [-3276.8|3276.7] "A" Vector__XXX
 SG_ INV_INV_Modulation_Index : 0|16@1- (0.0001,0) [-3.2768|3.2767] "" Vector__XXX

BO_ 172 M172_Torque_And_Timer_Info: 8 INV
 SG_ INV_INV_Power_On_Timer : 32|32@1+ (0.003,0) [0|12884800] "Sec" Vector__XXX
 SG_ INV_INV_Torque_Feedback : 16|16@1- (0.1,0) [-3276.8|3276.7] "Nm" Vector__XXX
 SG_ INV_INV_Commanded_Torque : 0|16@1- (0.1,0) [-3276.8|3276.7] "Nm" Vector__XXX

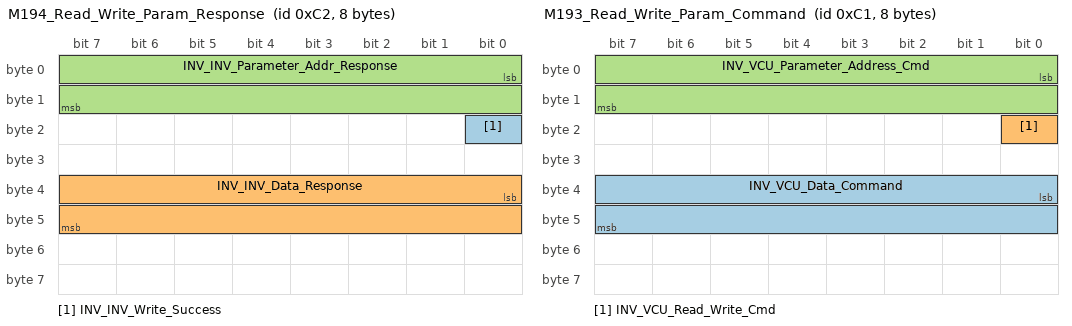
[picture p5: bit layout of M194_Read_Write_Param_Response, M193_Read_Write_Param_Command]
BO_ 194 M194_Read_Write_Param_Response: 8 INV
 SG_ INV_INV_Write_Success : 16|1@1+ (1,0) [0|1] "" Vector__XXX
 SG_ INV_INV_Data_Response : 32|16@1- (1,0) [-32768|32767] "" Vector__XXX
 SG_ INV_INV_Parameter_Addr_Response : 0|16@1+ (1,0) [0|65535] "" Vector__XXX

BO_ 193 M193_Read_Write_Param_Command: 8 VCU
 SG_ INV_VCU_Data_Command : 32|16@1- (1,0) [-32768|32767] "" Vector__XXX
 SG_ INV_VCU_Read_Write_Cmd : 16|1@1+ (1,0) [0|1] "" Vector__XXX
 SG_ INV_VCU_Parameter_Address_Cmd : 0|16@1+ (1,0) [0|65535] "" Vector__XXX

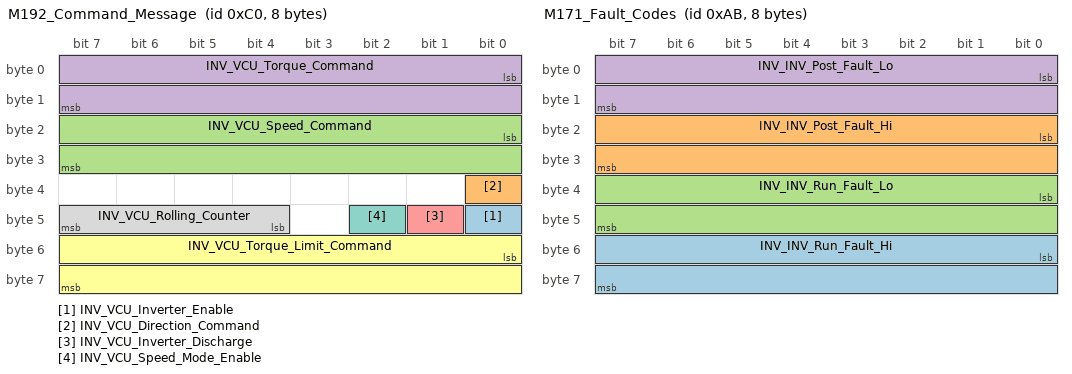
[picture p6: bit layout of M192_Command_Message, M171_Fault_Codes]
BO_ 192 M192_Command_Message: 8 VCU
 SG_ INV_VCU_Inverter_Enable : 40|1@1+ (1,0) [0|1] "Bit"  INV
 SG_ INV_VCU_Direction_Command : 32|1@1+ (1,0) [0|1] "Bit"  INV
 SG_ INV_VCU_Speed_Command : 16|16@1- (1,0) [-32768|32767] "rpm"  INV
 SG_ INV_VCU_Torque_Command : 0|16@1- (0.1,0) [-3276.8|3276.7] "Nm"  INV
 SG_ INV_VCU_Inverter_Discharge : 41|1@1+ (1,0) [0|1] "Bit"  INV
 SG_ INV_VCU_Torque_Limit_Command : 48|16@1- (0.1,0) [-3276.8|3276.7] "Nm"  INV
 SG_ INV_VCU_Speed_Mode_Enable : 42|1@1+ (1,0) [0|1] "Bit"  INV
 SG_ INV_VCU_Rolling_Counter : 44|4@1+ (1,0) [0|15] "Bits"  INV

BO_ 171 M171_Fault_Codes: 8 INV
 SG_ INV_INV_Run_Fault_Hi : 48|16@1+ (1,0) [0|65535] ""  VCU
 SG_ INV_INV_Post_Fault_Hi : 16|16@1+ (1,0) [0|65535] ""  VCU
 SG_ INV_INV_Run_Fault_Lo : 32|16@1+ (1,0) [0|65535] ""  VCU
 SG_ INV_INV_Post_Fault_Lo : 0|16@1+ (1,0) [0|65535] ""  VCU

BO_ 170 M170_Internal_States: 8 INV
 SG_ INV_INV_Direction_Command : 56|1@1+ (1,0) [0|1] ""  VCU
 SG_ INV_INV_Inverter_Enable_State : 48|1@1+ (1,0) [0|1] ""  VCU
 SG_ INV_INV_Relay_3_Status : 26|1@1+ (1,0) [0|1] ""  VCU
 SG_ INV_INV_Relay_4_Status : 27|1@1+ (1,0) [0|1] ""  VCU
 SG_ INV_INV_Relay_2_Status : 25|1@1+ (1,0) [0|1] ""  VCU
 SG_ INV_INV_Inverter_Run_Mode : 32|1@1+ (1,0) [0|1] ""  VCU
 SG_ INV_INV_Inverter_Command_Mode : 40|1@1+ (1,0) [0|1] ""  VCU
 SG_ INV_INV_Relay_1_Status : 24|1@1+ (1,0) [0|1] ""  VCU
 SG_ INV_INV_Inverter_State : 16|8@1+ (1,0) [0|255] ""  VCU
 SG_ INV_INV_VSM_State : 0|8@1+ (1,0) [0|15] ""  VCU
 SG_ INV_INV_Inverter_Enable_Lockout : 55|1@1+ (1,0) [0|1] ""  VCU
 SG_ INV_INV_Inverter_Discharge_State : 37|3@1+ (1,0) [0|7] ""  VCU
 SG_ INV_INV_Relay_5_Status : 28|1@1+ (1,0) [0|1] ""  VCU
 SG_ INV_INV_Relay_6_Status : 29|1@1+ (1,0) [0|1] ""  VCU
 SG_ INV_INV_BMS_Active : 57|1@1+ (1,0) [0|1] ""  VCU
 SG_ INV_INV_BMS_Torque_Limiting : 58|1@1+ (1,0) [0|1] ""  VCU
 SG_ INV_INV_Max_Speed_Limiting : 59|1@1+ (1,0) [0|1] ""  VCU
 SG_ INV_INV_Low_Speed_Limiting : 61|1@1+ (1,0) [0|1] ""  VCU
 SG_ INV_INV_Rolling_Counter : 44|4@1+ (1,0) [0|15] ""  VCU
 SG_ INV_INV_PWM_Frequency : 8|8@1+ (1,0) [0|255] "kHz"  VCU
 SG_ INV_INV_Start_Mode_Active : 54|1@1+ (1,0) [0|1] ""  VCU

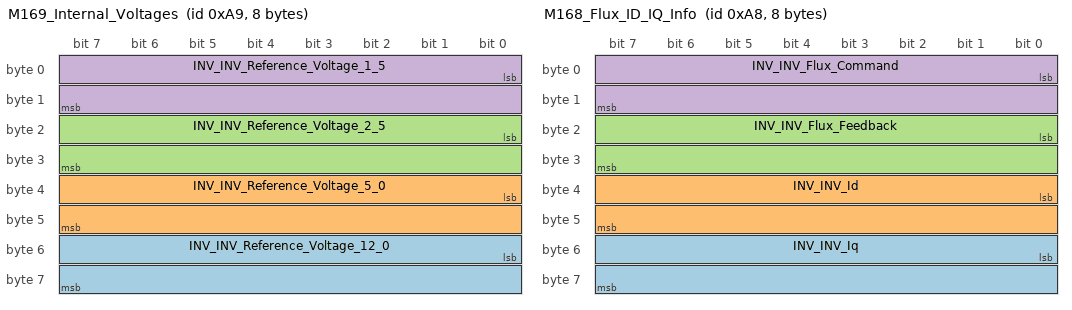
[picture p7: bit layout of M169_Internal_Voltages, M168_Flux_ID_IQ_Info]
BO_ 169 M169_Internal_Voltages: 8 INV
 SG_ INV_INV_Reference_Voltage_12_0 : 48|16@1- (0.01,0) [-327.68|327.67] "V" Vector__XXX
 SG_ INV_INV_Reference_Voltage_5_0 : 32|16@1- (0.01,0) [-327.68|327.67] "V" Vector__XXX
 SG_ INV_INV_Reference_Voltage_2_5 : 16|16@1- (0.01,0) [-327.68|327.67] "V" Vector__XXX
 SG_ INV_INV_Reference_Voltage_1_5 : 0|16@1- (0.01,0) [-327.68|327.67] "V" Vector__XXX

BO_ 168 M168_Flux_ID_IQ_Info: 8 INV
 SG_ INV_INV_Iq : 48|16@1- (0.1,0) [-3276.8|3276.7] "A" Vector__XXX
 SG_ INV_INV_Id : 32|16@1- (0.1,0) [-3276.8|3276.7] "A" Vector__XXX
 SG_ INV_INV_Flux_Feedback : 16|16@1- (0.001,0) [-32.768|32.767] "Wb" Vector__XXX
 SG_ INV_INV_Flux_Command : 0|16@1- (0.001,0) [-32.768|32.767] "Wb" Vector__XXX

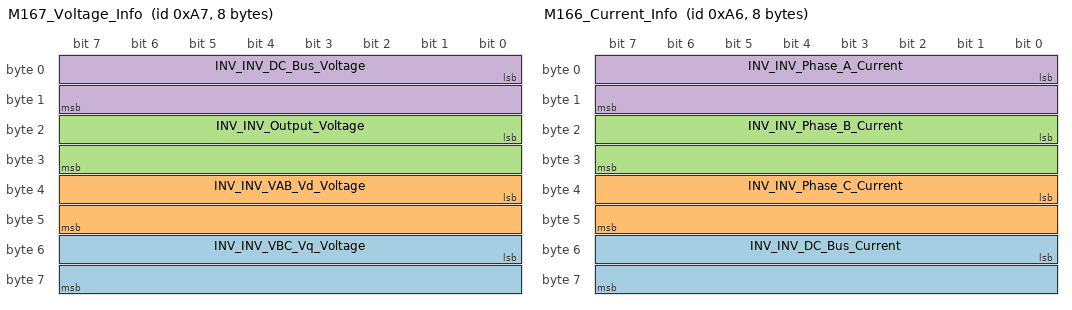
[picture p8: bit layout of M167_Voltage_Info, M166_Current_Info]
BO_ 167 M167_Voltage_Info: 8 INV
 SG_ INV_INV_VBC_Vq_Voltage : 48|16@1- (0.1,0) [-3276.8|3276.7] "V" Vector__XXX
 SG_ INV_INV_VAB_Vd_Voltage : 32|16@1- (0.1,0) [-3276.8|3276.7] "V" Vector__XXX
 SG_ INV_INV_Output_Voltage : 16|16@1- (0.1,0) [-3276.8|3276.7] "V" Vector__XXX
 SG_ INV_INV_DC_Bus_Voltage : 0|16@1- (0.1,0) [-3276.8|3276.7] "V" Vector__XXX

BO_ 166 M166_Current_Info: 8 INV
 SG_ INV_INV_DC_Bus_Current : 48|16@1- (0.1,0) [-3276.8|3276.7] "A" Vector__XXX
 SG_ INV_INV_Phase_C_Current : 32|16@1- (0.1,0) [-3276.8|3276.7] "A" Vector__XXX
 SG_ INV_INV_Phase_B_Current : 16|16@1- (0.1,0) [-3276.8|3276.7] "A" Vector__XXX
 SG_ INV_INV_Phase_A_Current : 0|16@1- (0.1,0) [-3276.8|3276.7] "A" Vector__XXX

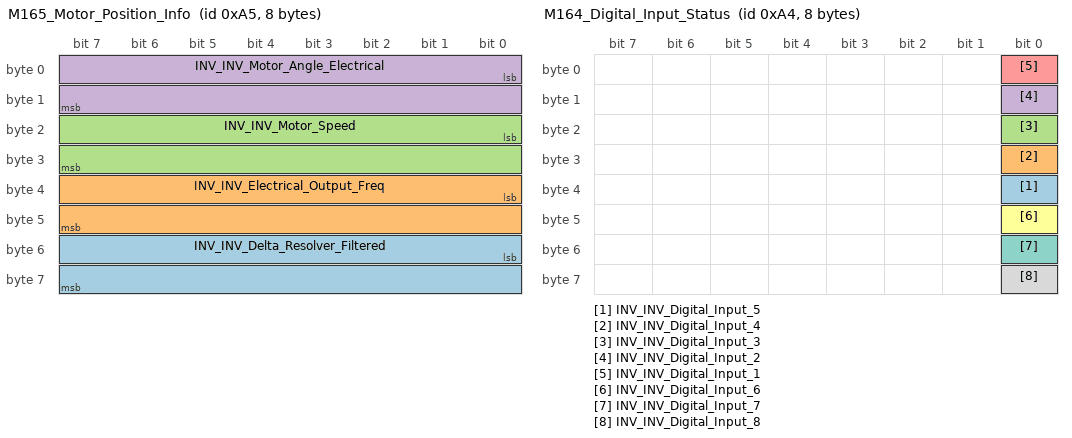
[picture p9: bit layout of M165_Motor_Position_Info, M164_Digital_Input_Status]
BO_ 165 M165_Motor_Position_Info: 8 INV
 SG_ INV_INV_Delta_Resolver_Filtered : 48|16@1- (0.1,0) [-3276.8|3276.7] "deg"  VCU
 SG_ INV_INV_Electrical_Output_Freq : 32|16@1- (0.1,0) [-3276.8|3276.7] "hz"  VCU
 SG_ INV_INV_Motor_Speed : 16|16@1- (1,0) [-32768|32767] "rpm"  VCU
 SG_ INV_INV_Motor_Angle_Electrical : 0|16@1+ (0.1,0) [0|6553.5] "deg"  VCU

BO_ 164 M164_Digital_Input_Status: 8 INV
 SG_ INV_INV_Digital_Input_5 : 32|1@1+ (1,0) [0|1] "boolean" Vector__XXX
 SG_ INV_INV_Digital_Input_4 : 24|1@1+ (1,0) [0|1] "boolean" Vector__XXX
 SG_ INV_INV_Digital_Input_3 : 16|1@1+ (1,0) [0|1] "boolean" Vector__XXX
 SG_ INV_INV_Digital_Input_2 : 8|1@1+ (1,0) [0|1] "boolean" Vector__XXX
 SG_ INV_INV_Digital_Input_1 : 0|1@1+ (1,0) [0|1] "boolean" Vector__XXX
 SG_ INV_INV_Digital_Input_6 : 40|1@1+ (1,0) [0|1] "boolean" Vector__XXX
 SG_ INV_INV_Digital_Input_7 : 48|1@1+ (1,0) [0|1] "boolean" Vector__XXX
 SG_ INV_INV_Digital_Input_8 : 56|1@1+ (1,0) [0|1] "boolean" Vector__XXX

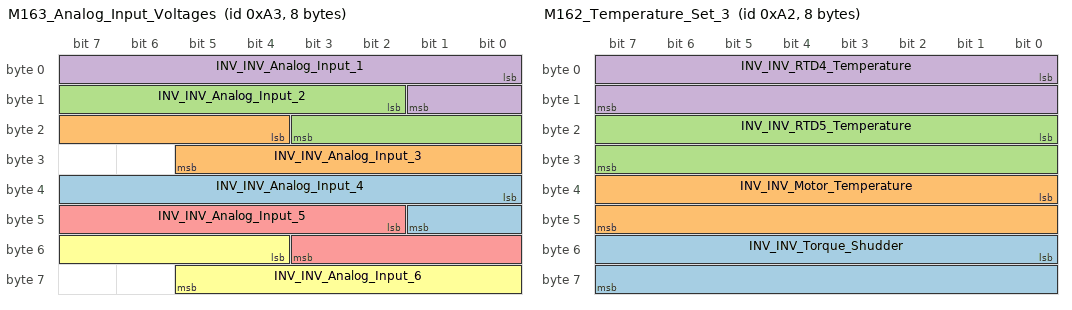
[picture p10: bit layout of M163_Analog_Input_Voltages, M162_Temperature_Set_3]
BO_ 163 M163_Analog_Input_Voltages: 8 INV
 SG_ INV_INV_Analog_Input_4 : 32|10@1+ (0.01,0) [0|10.23] "V" Vector__XXX
 SG_ INV_INV_Analog_Input_3 : 20|10@1+ (0.01,0) [0|10.23] "V" Vector__XXX
 SG_ INV_INV_Analog_Input_2 : 10|10@1+ (0.01,0) [0|10.23] "V" Vector__XXX
 SG_ INV_INV_Analog_Input_1 : 0|10@1+ (0.01,0) [0|10.23] "V" Vector__XXX
 SG_ INV_INV_Analog_Input_5 : 42|10@1+ (0.01,0) [0|10.23] "V" Vector__XXX
 SG_ INV_INV_Analog_Input_6 : 52|10@1+ (0.01,0) [0|10.23] "V" Vector__XXX

BO_ 162 M162_Temperature_Set_3: 8 INV
 SG_ INV_INV_Torque_Shudder : 48|16@1- (0.1,0) [-3276.8|3276.7] "Nm"  VCU
 SG_ INV_INV_Motor_Temperature : 32|16@1- (0.1,0) [-3276.8|3276.7] "degC"  VCU
 SG_ INV_INV_RTD5_Temperature : 16|16@1- (0.1,0) [-3276.8|3276.7] "degC"  VCU
 SG_ INV_INV_RTD4_Temperature : 0|16@1- (0.1,0) [-3276.8|3276.7] "degC"  VCU

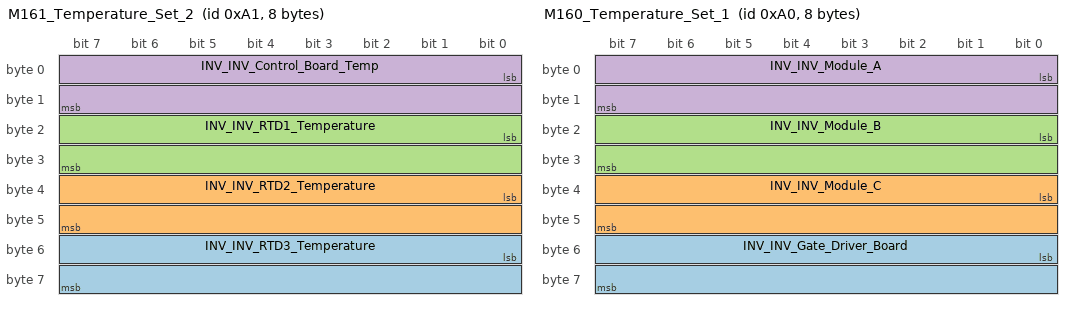
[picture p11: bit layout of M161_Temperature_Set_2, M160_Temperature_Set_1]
BO_ 161 M161_Temperature_Set_2: 8 INV
 SG_ INV_INV_RTD3_Temperature : 48|16@1- (0.1,0) [-3276.8|3276.7] "degC"  VCU
 SG_ INV_INV_RTD2_Temperature : 32|16@1- (0.1,0) [-3276.8|3276.7] "degC"  VCU
 SG_ INV_INV_RTD1_Temperature : 16|16@1- (0.1,0) [-3276.8|3276.7] "degC"  VCU
 SG_ INV_INV_Control_Board_Temp : 0|16@1- (0.1,0) [-3276.8|3276.7] "degC"  VCU

BO_ 160 M160_Temperature_Set_1: 8 INV
 SG_ INV_INV_Gate_Driver_Board : 48|16@1- (0.1,0) [-3276.8|3276.7] "degC"  VCU
 SG_ INV_INV_Module_C : 32|16@1- (0.1,0) [-3276.8|3276.7] "degC"  VCU
 SG_ INV_INV_Module_B : 16|16@1- (0.1,0) [-3276.8|3276.7] "degC"  VCU
 SG_ INV_INV_Module_A : 0|16@1- (0.1,0) [-3276.8|3276.7] "degC"  VCU

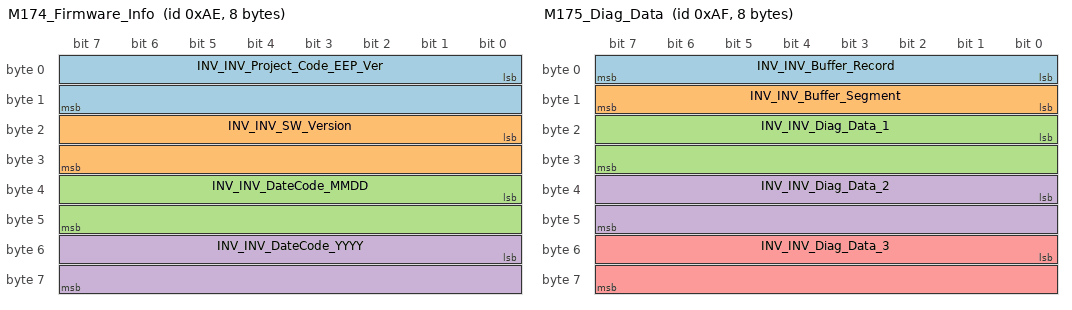
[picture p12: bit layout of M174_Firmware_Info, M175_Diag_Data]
BO_ 174 M174_Firmware_Info: 8 INV
 SG_ INV_INV_Project_Code_EEP_Ver : 0|16@1+ (1,0) [0|65535] "" Vector__XXX
 SG_ INV_INV_SW_Version : 16|16@1+ (1,0) [0|65535] "" Vector__XXX
 SG_ INV_INV_DateCode_MMDD : 32|16@1+ (1,0) [0|65535] "" Vector__XXX
 SG_ INV_INV_DateCode_YYYY : 48|16@1+ (1,0) [0|65535] "" Vector__XXX

BO_ 175 M175_Diag_Data: 8 INV
 SG_ INV_INV_Buffer_Record : 0|8@1+ (1,0) [0|255] "" Vector__XXX
 SG_ INV_INV_Buffer_Segment : 8|8@1+ (1,0) [0|5] "" Vector__XXX
 SG_ INV_INV_Diag_Data_1 : 16|16@1- (1,0) [-32768|32767] "" Vector__XXX
 SG_ INV_INV_Diag_Data_2 : 32|16@1- (1,0) [-32768|32767] "" Vector__XXX
 SG_ INV_INV_Diag_Data_3 : 48|16@1- (1,0) [-32768|32767] "" Vector__XXX

BO_ 471 M187_U2C_Command_Txd: 8 INV
 SG_ INV_INV_ID_Byte : 0|8@1+ (1,0) [0|255] "" Vector__XXX
 SG_ INV_INV_Setpoint_Calc : 8|8@1+ (1,0) [0|255] "" Vector__XXX

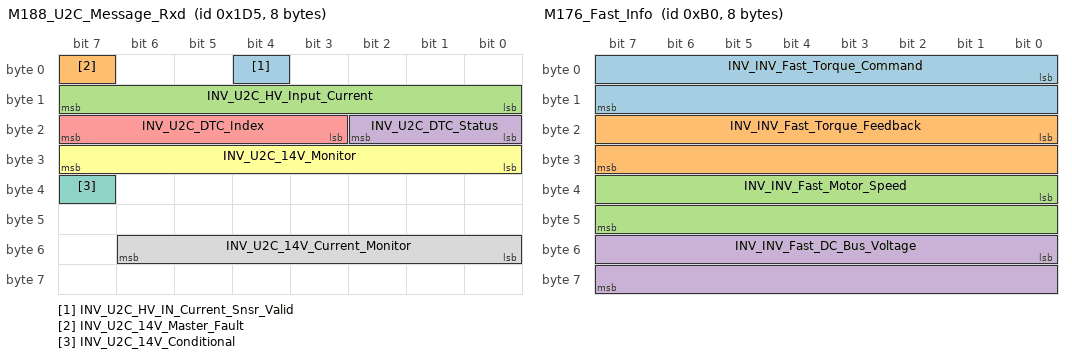
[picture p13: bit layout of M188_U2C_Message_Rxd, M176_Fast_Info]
BO_ 469 M188_U2C_Message_Rxd: 8 U2C
 SG_ INV_U2C_HV_IN_Current_Snsr_Valid : 4|1@1+ (1,0) [0|1] "" Vector__XXX
 SG_ INV_U2C_14V_Master_Fault : 7|1@1+ (1,0) [0|1] "" Vector__XXX
 SG_ INV_U2C_HV_Input_Current : 8|8@1+ (1,0) [0|255] "" Vector__XXX
 SG_ INV_U2C_DTC_Status : 16|3@1+ (1,0) [0|7] "" Vector__XXX
 SG_ INV_U2C_DTC_Index : 19|5@1+ (1,0) [0|31] "" Vector__XXX
 SG_ INV_U2C_14V_Monitor : 24|8@1+ (1,0) [0|255] "" Vector__XXX
 SG_ INV_U2C_14V_Conditional : 39|1@1+ (1,0) [0|1] "" Vector__XXX
 SG_ INV_U2C_14V_Current_Monitor : 48|7@1+ (1,0) [0|127] "" Vector__XXX

BO_ 514 BMS_Current_Limit: 8 BMS
 SG_ INV_BMS_Max_Discharge_Current : 0|16@1+ (1,0) [0|1000] "A"  INV
 SG_ INV_BMS_Max_Charge_Current : 16|16@1+ (1,0) [0|1000] "A"  INV

BO_ 176 M176_Fast_Info: 8 INV
 SG_ INV_INV_Fast_Torque_Command : 0|16@1- (0.1,0) [-3276.8|3276.7] "Nm" Vector__XXX
 SG_ INV_INV_Fast_Torque_Feedback : 16|16@1- (0.1,0) [-3276.8|3276.7] "Nm" Vector__XXX
 SG_ INV_INV_Fast_Motor_Speed : 32|16@1- (1,0) [-32768|32767] "rpm" Vector__XXX
 SG_ INV_INV_Fast_DC_Bus_Voltage : 48|16@1- (0.1,0) [-3276.8|3276.7] "V" Vector__XXX

CM_ BO_ 3221225472 "This is a message for not used signals, created by Vector CANdb++ DBC OLE DB Provider.";
